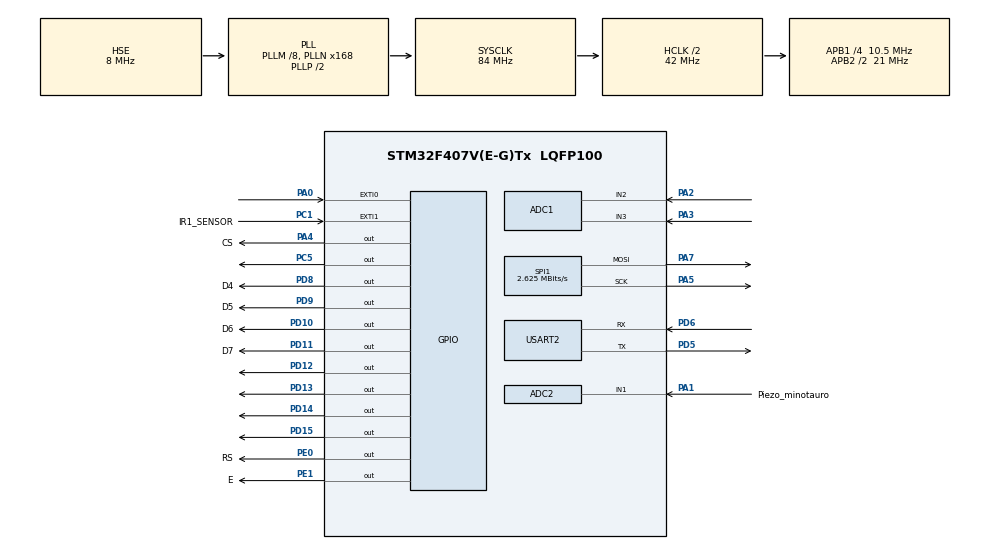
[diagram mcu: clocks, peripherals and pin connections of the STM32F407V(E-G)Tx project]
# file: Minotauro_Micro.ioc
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ADC1.Channel-0\#ChannelRegularConversion=ADC_CHANNEL_2
ADC1.Channel-1\#ChannelRegularConversion=ADC_CHANNEL_3
ADC1.ClockPrescaler=ADC_CLOCK_SYNC_PCLK_DIV4
ADC1.ContinuousConvMode=DISABLE
ADC1.NbrOfConversion=2
ADC1.NbrOfConversionFlag=1
ADC1.Rank-0\#ChannelRegularConversion=1
ADC1.Rank-1\#ChannelRegularConversion=2
ADC1.SamplingTime-0\#ChannelRegularConversion=ADC_SAMPLETIME_56CYCLES
ADC1.SamplingTime-1\#ChannelRegularConversion=ADC_SAMPLETIME_56CYCLES
ADC1.ScanConvMode=ENABLE
ADC1.master=1
ADC2.Channel-1\#ChannelRegularConversion=ADC_CHANNEL_1
ADC2.ClockPrescaler=ADC_CLOCK_SYNC_PCLK_DIV4
ADC2.ContinuousConvMode=ENABLE
ADC2.NbrOfConversionFlag=1
ADC2.Rank-1\#ChannelRegularConversion=1
ADC2.SamplingTime-1\#ChannelRegularConversion=ADC_SAMPLETIME_3CYCLES
FREERTOS.BinarySemaphores01=SemBinGolpe,Dynamic,NULL,Available
FREERTOS.Queues01=ColaEvento,16,uint8_t,0,Dynamic,NULL,NULL
FREERTOS.Tasks01=GameTask,24,256,StartGameTask,Default,NULL,Dynamic,NULL,NULL;Input_Task,40,128,Start_Input_Task,Default,NULL,Dynamic,NULL,NULL
FREERTOS.configUSE_NEWLIB_REENTRANT=1
Mcu.Family=STM32F4
Mcu.Name=STM32F407V(E-G)Tx
Mcu.Package=LQFP100
NVIC.EXTI0_IRQn=true\:5\:0\:true\:false\:true\:true\:true\:true\:true
NVIC.PriorityGroup=NVIC_PRIORITYGROUP_4
NVIC.TIM2_IRQn=true\:5\:0\:false\:false\:true\:true\:true\:true\:true
NVIC.TIM3_IRQn=true\:5\:0\:false\:false\:true\:true\:true\:true\:true
NVIC.TIM6_DAC_IRQn=true\:15\:0\:true\:false\:true\:false\:false\:true\:true
NVIC.TimeBase=TIM6_DAC_IRQn
NVIC.TimeBaseIP=TIM6
NVIC.USART2_IRQn=true\:5\:0\:false\:false\:true\:true\:true\:true\:true
PA0-WKUP.Signal=GPXTI0
PA1.GPIO_Label=Piezo_minotauro
PA1.Signal=ADCx_IN1
PA13.Mode=Serial_Wire
PA13.Signal=SYS_JTMS-SWDIO
PA14.Mode=Serial_Wire
PA14.Signal=SYS_JTCK-SWCLK
PA2.Signal=ADCx_IN2
PA3.Signal=ADCx_IN3
PA4.GPIO_Label=CS
PA4.Signal=GPIO_Output
PA5.Mode=TX_Only_Simplex_Unidirect_Master
PA5.Signal=SPI1_SCK
PA7.Mode=TX_Only_Simplex_Unidirect_Master
PA7.Signal=SPI1_MOSI
PC1.GPIO_Label=IR1_SENSOR
PC1.GPIO_ModeDefaultEXTI=GPIO_MODE_IT_FALLING
PC1.GPIO_PuPd=GPIO_PULLUP
PC1.Signal=GPXTI1
PC5.Signal=GPIO_Output
PD10.GPIO_Label=D6
PD10.Signal=GPIO_Output
PD11.GPIO_Label=D7
PD11.Signal=GPIO_Output
PD12.Signal=GPIO_Output
PD13.Signal=GPIO_Output
PD14.Signal=GPIO_Output
PD15.Signal=GPIO_Output
PD5.Mode=Asynchronous
PD5.Signal=USART2_TX
PD6.Mode=Asynchronous
PD6.Signal=USART2_RX
PD8.GPIO_Label=D4
PD8.Signal=GPIO_Output
PD9.GPIO_Label=D5
PD9.Signal=GPIO_Output
PE0.GPIO_Label=RS
PE0.Signal=GPIO_Output
PE1.GPIO_Label=E
PE1.Signal=GPIO_Output
PH0-OSC_IN.Mode=HSE-External-Oscillator
PH0-OSC_IN.Signal=RCC_OSC_IN
PH1-OSC_OUT.Mode=HSE-External-Oscillator
PH1-OSC_OUT.Signal=RCC_OSC_OUT
ProjectManager.HeapSize=0x200
ProjectManager.StackSize=0x400
ProjectManager.TargetToolchain=STM32CubeIDE
RCC.48MHZClocksFreq_Value=24000000
RCC.AHBCLKDivider=RCC_SYSCLK_DIV2
RCC.AHBFreq_Value=42000000
RCC.APB1CLKDivider=RCC_HCLK_DIV4
RCC.APB1Freq_Value=10500000
RCC.APB1TimFreq_Value=21000000
RCC.APB2CLKDivider=RCC_HCLK_DIV2
RCC.APB2Freq_Value=21000000
RCC.APB2TimFreq_Value=42000000
RCC.CortexFreq_Value=42000000
RCC.HCLKFreq_Value=42000000
RCC.HSE_VALUE=8000000
RCC.HSI_VALUE=16000000
RCC.LSE_VALUE=32768
RCC.PLLM=8
RCC.PLLN=168
RCC.PLLQ=7
RCC.PLLSourceVirtual=RCC_PLLSOURCE_HSE
RCC.SYSCLKFreq_VALUE=84000000
RCC.SYSCLKSource=RCC_SYSCLKSOURCE_PLLCLK
RCC.VCOOutputFreq_Value=168000000
SH.ADCx_IN1.0=ADC2_IN1,IN1
SH.ADCx_IN2.0=ADC1_IN2,IN2
SH.ADCx_IN3.0=ADC1_IN3,IN3
SPI1.BaudRatePrescaler=SPI_BAUDRATEPRESCALER_8
SPI1.CalculateBaudRate=2.625 MBits/s
SPI1.DataSize=SPI_DATASIZE_16BIT
SPI1.Direction=SPI_DIRECTION_2LINES
SPI1.Mode=SPI_MODE_MASTER
SPI1.VirtualType=VM_MASTER
TIM2.AutoReloadPreload=TIM_AUTORELOAD_PRELOAD_ENABLE
TIM2.Period=9999
TIM2.Prescaler=4199
TIM3.Period=999
TIM3.Prescaler=2099
USART2.VirtualMode=VM_ASYNC
VP_FREERTOS_VS_CMSIS_V2.Mode=CMSIS_V2
VP_SYS_VS_tim6.Mode=TIM6
VP_TIM2_VS_ClockSourceINT.Mode=Internal
VP_TIM3_VS_ClockSourceINT.Mode=Internal
board=STM32F407G-DISC1

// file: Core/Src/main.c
/* USER CODE BEGIN Header */
/**
  ******************************************************************************
  * @file           : main.c
  * @brief          : Main program body
  ******************************************************************************
  * @attention
  *
  * Copyright (c) 2025 STMicroelectronics.
  * All rights reserved.
  *
  * This software is licensed under terms that can be found in the LICENSE file
  * in the root directory of this software component.
  * If no LICENSE file comes with this software, it is provided AS-IS.
  *
  ******************************************************************************
  */
/* USER CODE END Header */
#include "main.h"
#include "cmsis_os.h"

/* USER CODE BEGIN PD */
//flags definidas
#define FLAG_GOLPE  0x00000001U
#define FLAG_IR     0x00000002U
#define FLAG_CAMBIO 0x00000003U
/* USER CODE END PD */

ADC_HandleTypeDef hadc1;
ADC_HandleTypeDef hadc2;

SPI_HandleTypeDef hspi1;

TIM_HandleTypeDef htim2;
TIM_HandleTypeDef htim3;

UART_HandleTypeDef huart2;

/* Definitions for GameTask */
osThreadId_t GameTaskHandle;
const osThreadAttr_t GameTask_attributes = {
  .name = "GameTask",
  .stack_size = 256 * 4,
  .priority = (osPriority_t) osPriorityNormal,
};
/* Definitions for Input_Task */
osThreadId_t Input_TaskHandle;
const osThreadAttr_t Input_Task_attributes = {
  .name = "Input_Task",
  .stack_size = 128 * 4,
  .priority = (osPriority_t) osPriorityHigh,
};
/* Definitions for ColaEvento */
osMessageQueueId_t ColaEventoHandle;
const osMessageQueueAttr_t ColaEvento_attributes = {
  .name = "ColaEvento"
};

//Definitions for FPGA_COM_Task
osThreadId_t FPGA_COM_TaskHandle;
const osThreadAttr_t FPGA_COM_Task_attributes = {
  .name = "FPGA_COM_Task",
  .stack_size = 128 * 4,
  .priority = (osPriority_t) osPriorityHigh,
};

/* Definición Global (fuera de funciones) */
osEventFlagsId_t InputEventsHandle;

const osEventFlagsAttr_t InputEvents_attributes = {
  .name = "InputEvents"
};

void SystemClock_Config(void);
static void MX_GPIO_Init(void);
static void MX_TIM2_Init(void);
static void MX_USART2_UART_Init(void);
static void MX_ADC1_Init(void);
static void MX_ADC2_Init(void);
static void MX_TIM3_Init(void);
static void MX_SPI1_Init(void);
void StartGameTask(void *argument);
void Start_Input_Task(void *argument);
void StartFPGA_COM_Task(void *argument);

int main(void)
{

  /* MCU Configuration--------------------------------------------------------*/

  /* Reset of all peripherals, Initializes the Flash interface and the Systick. */
  HAL_Init();

  /* Configure the system clock */
  SystemClock_Config();

  /* Initialize all configured peripherals */
  MX_GPIO_Init();
  MX_TIM2_Init();
  MX_USART2_UART_Init();
  MX_ADC1_Init();
  MX_ADC2_Init();
  MX_TIM3_Init();
  MX_SPI1_Init();
  /* USER CODE BEGIN 2 */

  // INICIALIZACIÓN DEL LCD
    LCD1602_Begin4BIT(GPIOE, RS_Pin, E_Pin, GPIOD, D4_Pin, D5_Pin, D6_Pin, D7_Pin);

    // Imprimimos el mensaje en pantalla
    /*LCD1602_print("  El MINOTAURO");
    LCD1602_2ndLine();
    LCD1602_print("    A jugar");
    LCD1602_noBlink();*/
  /* USER CODE END 2 */

  /* Init scheduler */
  osKernelInitialize();

  /* Create the semaphores(s) */
  /* creation of SemBinGolpe */
  //SemBinGolpeHandle = osSemaphoreNew(1, 1, &SemBinGolpe_attributes);
  //Flags
    InputEventsHandle = osEventFlagsNew(&InputEvents_attributes);
  /* USER CODE BEGIN RTOS_SEMAPHORES */
  /* add semaphores, ... */
  /* creation of SemBinIR */
  //SemBinIRHandle = osSemaphoreNew(1, 1, &SemBinIR_attributes);
  /* USER CODE END RTOS_SEMAPHORES */

  /* Create the queue(s) */
  /* creation of ColaEvento */
  ColaEventoHandle = osMessageQueueNew (16, sizeof(uint8_t), &ColaEvento_attributes);

  /* Create the thread(s) */
  /* creation of GameTask */
  GameTaskHandle = osThreadNew(StartGameTask, NULL, &GameTask_attributes);

  /* creation of Input_Task */
  Input_TaskHandle = osThreadNew(Start_Input_Task, NULL, &Input_Task_attributes);

  //Creation of FPGA_COM_Task
  FPGA_COM_TaskHandle = osThreadNew(StartFPGA_COM_Task, NULL, &FPGA_COM_Task_attributes);

  /* Start scheduler */
  osKernelStart();

  /* We should never get here as control is now taken by the scheduler */

  /* Infinite loop */
  while (1)
  {

  }
}

void SystemClock_Config(void)
{
  RCC_OscInitTypeDef RCC_OscInitStruct = {0};
  RCC_ClkInitTypeDef RCC_ClkInitStruct = {0};

  /** Configure the main internal regulator output voltage
  */
  __HAL_RCC_PWR_CLK_ENABLE();
  __HAL_PWR_VOLTAGESCALING_CONFIG(PWR_REGULATOR_VOLTAGE_SCALE1);

  /** Initializes the RCC Oscillators according to the specified parameters
  * in the RCC_OscInitTypeDef structure.
  */
  RCC_OscInitStruct.OscillatorType = RCC_OSCILLATORTYPE_HSE;
  RCC_OscInitStruct.HSEState = RCC_HSE_ON;
  RCC_OscInitStruct.PLL.PLLState = RCC_PLL_ON;
  RCC_OscInitStruct.PLL.PLLSource = RCC_PLLSOURCE_HSE;
  RCC_OscInitStruct.PLL.PLLM = 8;
  RCC_OscInitStruct.PLL.PLLN = 168;
  RCC_OscInitStruct.PLL.PLLP = RCC_PLLP_DIV2;
  RCC_OscInitStruct.PLL.PLLQ = 7;
  if (HAL_RCC_OscConfig(&RCC_OscInitStruct) != HAL_OK)
  {
    Error_Handler();
  }

  /** Initializes the CPU, AHB and APB buses clocks
  */
  RCC_ClkInitStruct.ClockType = RCC_CLOCKTYPE_HCLK|RCC_CLOCKTYPE_SYSCLK
                              |RCC_CLOCKTYPE_PCLK1|RCC_CLOCKTYPE_PCLK2;
  RCC_ClkInitStruct.SYSCLKSource = RCC_SYSCLKSOURCE_PLLCLK;
  RCC_ClkInitStruct.AHBCLKDivider = RCC_SYSCLK_DIV2;
  RCC_ClkInitStruct.APB1CLKDivider = RCC_HCLK_DIV4;
  RCC_ClkInitStruct.APB2CLKDivider = RCC_HCLK_DIV2;

  if (HAL_RCC_ClockConfig(&RCC_ClkInitStruct, FLASH_LATENCY_1) != HAL_OK)
  {
    Error_Handler();
  }
}

static void MX_ADC1_Init(void)
{

  ADC_ChannelConfTypeDef sConfig = {0};

  /** Configure the global features of the ADC (Clock, Resolution, Data Alignment and number of conversion)
  */
  hadc1.Instance = ADC1;
  hadc1.Init.ClockPrescaler = ADC_CLOCK_SYNC_PCLK_DIV4;
  hadc1.Init.Resolution = ADC_RESOLUTION_12B;
  hadc1.Init.ScanConvMode = ENABLE;
  hadc1.Init.ContinuousConvMode = DISABLE;
  hadc1.Init.DiscontinuousConvMode = DISABLE;
  hadc1.Init.ExternalTrigConvEdge = ADC_EXTERNALTRIGCONVEDGE_NONE;
  hadc1.Init.ExternalTrigConv = ADC_SOFTWARE_START;
  hadc1.Init.DataAlign = ADC_DATAALIGN_RIGHT;
  hadc1.Init.NbrOfConversion = 2;
  hadc1.Init.DMAContinuousRequests = DISABLE;
  hadc1.Init.EOCSelection = ADC_EOC_SINGLE_CONV;
  if (HAL_ADC_Init(&hadc1) != HAL_OK)
  {
    Error_Handler();
  }

  /** Configure for the selected ADC regular channel its corresponding rank in the sequencer and its sample time.
  */
  sConfig.Channel = ADC_CHANNEL_2;
  sConfig.Rank = 1;
  sConfig.SamplingTime = ADC_SAMPLETIME_56CYCLES;
  if (HAL_ADC_ConfigChannel(&hadc1, &sConfig) != HAL_OK)
  {
    Error_Handler();
  }

  /** Configure for the selected ADC regular channel its corresponding rank in the sequencer and its sample time.
  */
  sConfig.Channel = ADC_CHANNEL_3;
  sConfig.Rank = 2;
  if (HAL_ADC_ConfigChannel(&hadc1, &sConfig) != HAL_OK)
  {
    Error_Handler();
  }

}

static void MX_ADC2_Init(void)
{

  ADC_ChannelConfTypeDef sConfig = {0};

  /** Configure the global features of the ADC (Clock, Resolution, Data Alignment and number of conversion)
  */
  hadc2.Instance = ADC2;
  hadc2.Init.ClockPrescaler = ADC_CLOCK_SYNC_PCLK_DIV4;
  hadc2.Init.Resolution = ADC_RESOLUTION_12B;
  hadc2.Init.ScanConvMode = DISABLE;
  hadc2.Init.ContinuousConvMode = ENABLE;
  hadc2.Init.DiscontinuousConvMode = DISABLE;
  hadc2.Init.ExternalTrigConvEdge = ADC_EXTERNALTRIGCONVEDGE_NONE;
  hadc2.Init.ExternalTrigConv = ADC_SOFTWARE_START;
  hadc2.Init.DataAlign = ADC_DATAALIGN_RIGHT;
  hadc2.Init.NbrOfConversion = 1;
  hadc2.Init.DMAContinuousRequests = DISABLE;
  hadc2.Init.EOCSelection = ADC_EOC_SINGLE_CONV;
  if (HAL_ADC_Init(&hadc2) != HAL_OK)
  {
    Error_Handler();
  }

  /** Configure for the selected ADC regular channel its corresponding rank in the sequencer and its sample time.
  */
  sConfig.Channel = ADC_CHANNEL_1;
  sConfig.Rank = 1;
  sConfig.SamplingTime = ADC_SAMPLETIME_3CYCLES;
  if (HAL_ADC_ConfigChannel(&hadc2, &sConfig) != HAL_OK)
  {
    Error_Handler();
  }

}

static void MX_SPI1_Init(void)
{

  /* SPI1 parameter configuration*/
  hspi1.Instance = SPI1;
  hspi1.Init.Mode = SPI_MODE_MASTER;
  hspi1.Init.Direction = SPI_DIRECTION_2LINES;
  hspi1.Init.DataSize = SPI_DATASIZE_16BIT;
  hspi1.Init.CLKPolarity = SPI_POLARITY_LOW;
  hspi1.Init.CLKPhase = SPI_PHASE_1EDGE;
  hspi1.Init.NSS = SPI_NSS_SOFT;
  hspi1.Init.BaudRatePrescaler = SPI_BAUDRATEPRESCALER_8;
  hspi1.Init.FirstBit = SPI_FIRSTBIT_MSB;
  hspi1.Init.TIMode = SPI_TIMODE_DISABLE;
  hspi1.Init.CRCCalculation = SPI_CRCCALCULATION_DISABLE;
  hspi1.Init.CRCPolynomial = 10;
  if (HAL_SPI_Init(&hspi1) != HAL_OK)
  {
    Error_Handler();
  }

}

static void MX_TIM2_Init(void)
{

  TIM_ClockConfigTypeDef sClockSourceConfig = {0};
  TIM_MasterConfigTypeDef sMasterConfig = {0};

  htim2.Instance = TIM2;
  htim2.Init.Prescaler = 4199;
  htim2.Init.CounterMode = TIM_COUNTERMODE_UP;
  htim2.Init.Period = 4999;
  htim2.Init.ClockDivision = TIM_CLOCKDIVISION_DIV1;
  htim2.Init.AutoReloadPreload = TIM_AUTORELOAD_PRELOAD_ENABLE;
  if (HAL_TIM_Base_Init(&htim2) != HAL_OK)
  {
    Error_Handler();
  }
  sClockSourceConfig.ClockSource = TIM_CLOCKSOURCE_INTERNAL;
  if (HAL_TIM_ConfigClockSource(&htim2, &sClockSourceConfig) != HAL_OK)
  {
    Error_Handler();
  }
  sMasterConfig.MasterOutputTrigger = TIM_TRGO_RESET;
  sMasterConfig.MasterSlaveMode = TIM_MASTERSLAVEMODE_DISABLE;
  if (HAL_TIMEx_MasterConfigSynchronization(&htim2, &sMasterConfig) != HAL_OK)
  {
    Error_Handler();
  }

}

static void MX_TIM3_Init(void)
{

  TIM_ClockConfigTypeDef sClockSourceConfig = {0};
  TIM_MasterConfigTypeDef sMasterConfig = {0};

  htim3.Instance = TIM3;
  htim3.Init.Prescaler = 2099;
  htim3.Init.CounterMode = TIM_COUNTERMODE_UP;
  htim3.Init.Period = 999;
  htim3.Init.ClockDivision = TIM_CLOCKDIVISION_DIV1;
  htim3.Init.AutoReloadPreload = TIM_AUTORELOAD_PRELOAD_DISABLE;
  if (HAL_TIM_Base_Init(&htim3) != HAL_OK)
  {
    Error_Handler();
  }
  sClockSourceConfig.ClockSource = TIM_CLOCKSOURCE_INTERNAL;
  if (HAL_TIM_ConfigClockSource(&htim3, &sClockSourceConfig) != HAL_OK)
  {
    Error_Handler();
  }
  sMasterConfig.MasterOutputTrigger = TIM_TRGO_RESET;
  sMasterConfig.MasterSlaveMode = TIM_MASTERSLAVEMODE_DISABLE;
  if (HAL_TIMEx_MasterConfigSynchronization(&htim3, &sMasterConfig) != HAL_OK)
  {
    Error_Handler();
  }

}

static void MX_USART2_UART_Init(void)
{

  huart2.Instance = USART2;
  huart2.Init.BaudRate = 115200;
  huart2.Init.WordLength = UART_WORDLENGTH_8B;
  huart2.Init.StopBits = UART_STOPBITS_1;
  huart2.Init.Parity = UART_PARITY_NONE;
  huart2.Init.Mode = UART_MODE_TX_RX;
  huart2.Init.HwFlowCtl = UART_HWCONTROL_NONE;
  huart2.Init.OverSampling = UART_OVERSAMPLING_16;
  if (HAL_UART_Init(&huart2) != HAL_OK)
  {
    Error_Handler();
  }

}

static void MX_GPIO_Init(void)
{
  GPIO_InitTypeDef GPIO_InitStruct = {0};

  /* GPIO Ports Clock Enable */
  __HAL_RCC_GPIOH_CLK_ENABLE();
  __HAL_RCC_GPIOC_CLK_ENABLE();
  __HAL_RCC_GPIOA_CLK_ENABLE();
  __HAL_RCC_GPIOD_CLK_ENABLE();
  __HAL_RCC_GPIOE_CLK_ENABLE();

  /*Configure GPIO pin Output Level */
  HAL_GPIO_WritePin(CS_GPIO_Port, CS_Pin, GPIO_PIN_RESET);

  /*Configure GPIO pin Output Level */
  HAL_GPIO_WritePin(GPIOC, GPIO_PIN_5, GPIO_PIN_RESET);

  /*Configure GPIO pin Output Level */
  HAL_GPIO_WritePin(GPIOD, D4_Pin|D5_Pin|D6_Pin|D7_Pin
                          |GPIO_PIN_12|GPIO_PIN_13|GPIO_PIN_14|GPIO_PIN_15, GPIO_PIN_RESET);

  /*Configure GPIO pin Output Level */
  HAL_GPIO_WritePin(GPIOE, RS_Pin|E_Pin, GPIO_PIN_RESET);

  /*Configure GPIO pin : IR1_SENSOR_Pin */
  GPIO_InitStruct.Pin = IR1_SENSOR_Pin;
  GPIO_InitStruct.Mode = GPIO_MODE_IT_FALLING;
  GPIO_InitStruct.Pull = GPIO_PULLUP;
  HAL_GPIO_Init(IR1_SENSOR_GPIO_Port, &GPIO_InitStruct);

  /*Configure GPIO pin : PA0 */
  GPIO_InitStruct.Pin = GPIO_PIN_0;
  GPIO_InitStruct.Mode = GPIO_MODE_IT_RISING;
  GPIO_InitStruct.Pull = GPIO_NOPULL;
  HAL_GPIO_Init(GPIOA, &GPIO_InitStruct);

  /*Configure GPIO pin : CS_Pin */
  GPIO_InitStruct.Pin = CS_Pin;
  GPIO_InitStruct.Mode = GPIO_MODE_OUTPUT_PP;
  GPIO_InitStruct.Pull = GPIO_NOPULL;
  GPIO_InitStruct.Speed = GPIO_SPEED_FREQ_LOW;
  HAL_GPIO_Init(CS_GPIO_Port, &GPIO_InitStruct);

  /*Configure GPIO pin : PC5 */
  GPIO_InitStruct.Pin = GPIO_PIN_5;
  GPIO_InitStruct.Mode = GPIO_MODE_OUTPUT_PP;
  GPIO_InitStruct.Pull = GPIO_NOPULL;
  GPIO_InitStruct.Speed = GPIO_SPEED_FREQ_LOW;
  HAL_GPIO_Init(GPIOC, &GPIO_InitStruct);

  /*Configure GPIO pins : D4_Pin D5_Pin D6_Pin D7_Pin
                           PD12 PD13 PD14 PD15 */
  GPIO_InitStruct.Pin = D4_Pin|D5_Pin|D6_Pin|D7_Pin
                          |GPIO_PIN_12|GPIO_PIN_13|GPIO_PIN_14|GPIO_PIN_15;
  GPIO_InitStruct.Mode = GPIO_MODE_OUTPUT_PP;
  GPIO_InitStruct.Pull = GPIO_NOPULL;
  GPIO_InitStruct.Speed = GPIO_SPEED_FREQ_LOW;
  HAL_GPIO_Init(GPIOD, &GPIO_InitStruct);

  /*Configure GPIO pins : RS_Pin E_Pin */
  GPIO_InitStruct.Pin = RS_Pin|E_Pin;
  GPIO_InitStruct.Mode = GPIO_MODE_OUTPUT_PP;
  GPIO_InitStruct.Pull = GPIO_NOPULL;
  GPIO_InitStruct.Speed = GPIO_SPEED_FREQ_LOW;
  HAL_GPIO_Init(GPIOE, &GPIO_InitStruct);

  /* EXTI interrupt init*/
  HAL_NVIC_SetPriority(EXTI0_IRQn, 5, 0);
  //HAL_NVIC_EnableIRQ(EXTI0_IRQn);

  HAL_NVIC_SetPriority(EXTI1_IRQn, 5, 0);
  //HAL_NVIC_EnableIRQ(EXTI1_IRQn);
}

void HAL_TIM_PeriodElapsedCallback(TIM_HandleTypeDef *htim)
{
  if (htim->Instance == TIM6)
  {
    HAL_IncTick();
  }
  /* USER CODE BEGIN Callback 1 */
  if (htim->Instance == TIM2)//esta interrupcion se ejecuta cada segundo
  {
	  Temp_Tick_Turno();
  }
  if (htim->Instance == TIM3) {
      	// Enviamos la señal (Flag) directamente
      	 osEventFlagsSet(InputEventsHandle, FLAG_GOLPE);
          //golpe_detectado = 0; // Permite detectar el siguiente golpe
          HAL_TIM_Base_Stop_IT(&htim3); // Detiene el timer
      }

  /* USER CODE END Callback 1 */
}

void Error_Handler(void)
{
  __disable_irq();
  while (1)
  {
  }
}
